# MKV31F25612 register map
Vendor: Freescale Semiconductor, Inc.; Series: Kinetis_V; File version: 1.6
CPU: CM4 r0p1, little endian, no MPU, FPU, VTOR, 4 interrupt priority bits
Registers are 32-bit, read-write, reset 0x0 unless marked. A register's access mark holds for its fields unless they carry their own. Offsets are from the block's base; [hi:lo] are bit positions; {n}, {i} and the like mark numbered series.

## DAC0 — 12-Bit Digital-to-Analog Converter
Base 0x4003F000; register names take the prefix DAC0_
{0x0+2i} DAT{i}L (i=0..15) 8-bit — DAC Data Low Register
  [7:0] DATA0 — When the DAC buffer is not enabled, DATA[11:0] controls the output voltage based on the following formula: V out = V in * (1 + DACDAT0[11:0])/4096 When the DAC buffer is enabled, DATA is mapped to the 16-word buffer
{0x1+2i} DAT{i}H (i=0..15) 8-bit — DAC Data High Register
  [3:0] DATA1 — When the DAC Buffer is not enabled, DATA[11:0] controls the output voltage based on the following formula
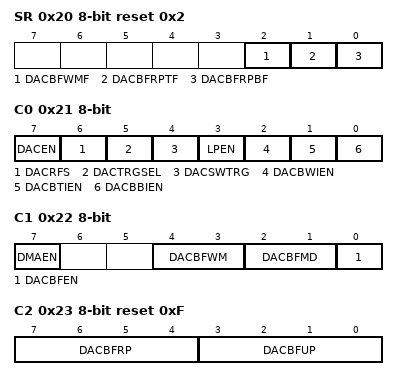
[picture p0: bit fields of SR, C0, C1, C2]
0x20 SR 8-bit reset 0x2 — DAC Status Register
  [2] DACBFWMF — DAC Buffer Watermark Flag
    0=The DAC buffer read pointer has not reached the watermark level; 1=The DAC buffer read pointer has reached the watermark level
  [1] DACBFRPTF — DAC Buffer Read Pointer Top Position Flag
    0=The DAC buffer read pointer is not zero; 1=The DAC buffer read pointer is zero
  [0] DACBFRPBF — DAC Buffer Read Pointer Bottom Position Flag
    0=The DAC buffer read pointer is not equal to C2[DACBFUP]; 1=The DAC buffer read pointer is equal to C2[DACBFUP]
0x21 C0 8-bit — DAC Control Register
  [7] DACEN — DAC Enable
    0=The DAC system is disabled; 1=The DAC system is enabled
  [6] DACRFS — DAC Reference Select
    0=The DAC selects DACREF_1 as the reference voltage; 1=The DAC selects DACREF_2 as the reference voltage
  [5] DACTRGSEL — DAC Trigger Select
    0=The DAC hardware trigger is selected; 1=The DAC software trigger is selected
  [4] DACSWTRG wo — DAC Software Trigger
    0=The DAC soft trigger is not valid; 1=The DAC soft trigger is valid
  [3] LPEN — DAC Low Power Control
    0=High-Power mode; 1=Low-Power mode
  [2] DACBWIEN — DAC Buffer Watermark Interrupt Enable
    0=The DAC buffer watermark interrupt is disabled; 1=The DAC buffer watermark interrupt is enabled
  [1] DACBTIEN — DAC Buffer Read Pointer Top Flag Interrupt Enable
    0=The DAC buffer read pointer top flag interrupt is disabled; 1=The DAC buffer read pointer top flag interrupt is enabled
  [0] DACBBIEN — DAC Buffer Read Pointer Bottom Flag Interrupt Enable
    0=The DAC buffer read pointer bottom flag interrupt is disabled; 1=The DAC buffer read pointer bottom flag interrupt is enabled
0x22 C1 8-bit — DAC Control Register 1
  [7] DMAEN — DMA Enable Select
    0=DMA is disabled; 1=DMA is enabled. When DMA is enabled, the DMA request will be generated by original interrupts. The interrupts will not be presented on this module at the same time.
  [4:3] DACBFWM — DAC Buffer Watermark Select
    0=In normal mode, 1 word . In FIFO mode, 2 or less than 2 data remaining in FIFO will set watermark status bit.; 1=In normal mode, 2 words . In FIFO mode, Max/4 or less than Max/4 data remaining in FIFO will set watermark status bit.; 2=In normal mode, 3 words . In FIFO mode, Max/2 or less than Max/2 data remaining in FIFO will set watermark status bit.; 3=In normal mode, 4 words . In FIFO mode, Max-2 or less than Max-2 data remaining in FIFO will set watermark status bit.
  [2:1] DACBFMD — DAC Buffer Work Mode Select
    0=Normal mode; 1=Swing mode; 2=One-Time Scan mode; 3=FIFO mode
  [0] DACBFEN — DAC Buffer Enable
    0=Buffer read pointer is disabled. The converted data is always the first word of the buffer.; 1=Buffer read pointer is enabled. The converted data is the word that the read pointer points to. It means converted data can be from any word of the buffer.
0x23 C2 8-bit reset 0xF — DAC Control Register 2
  [7:4] DACBFRP — DAC Buffer Read Pointer
  [3:0] DACBFUP — DAC Buffer Upper Limit

## LPTMR0 — Low Power Timer
Base 0x40040000; register names take the prefix LPTMR0_
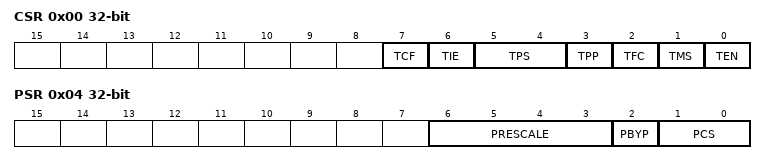
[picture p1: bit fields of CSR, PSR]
0x00 CSR — Low Power Timer Control Status Register
  [7] TCF — Timer Compare Flag
    0=The value of CNR is not equal to CMR and increments; 1=The value of CNR is equal to CMR and increments
  [6] TIE — Timer Interrupt Enable
    0=Timer interrupt disabled; 1=Timer interrupt enabled
  [5:4] TPS — Timer Pin Select
    {v}=Pulse counter input {v} is selected (v=0..3)
  [3] TPP — Timer Pin Polarity
    0=Pulse Counter input source is active-high, and the CNR will increment on the rising-edge; 1=Pulse Counter input source is active-low, and the CNR will increment on the falling-edge
  [2] TFC — Timer Free-Running Counter
    0=CNR is reset whenever TCF is set; 1=CNR is reset on overflow
  [1] TMS — Timer Mode Select
    0=Time Counter mode; 1=Pulse Counter mode
  [0] TEN — Timer Enable
    0=LPTMR is disabled and internal logic is reset; 1=LPTMR is enabled
0x04 PSR — Low Power Timer Prescale Register
  [6:3] PRESCALE — Prescale Value
    0=Prescaler divides the prescaler clock by 2; glitch filter does not support this configuration; 1=Prescaler divides the prescaler clock by 4; glitch filter recognizes change on input pin after 2 rising clock edges; 2=Prescaler divides the prescaler clock by 8; glitch filter recognizes change on input pin after 4 rising clock edges; 3=Prescaler divides the prescaler clock by 16; glitch filter recognizes change on input pin after 8 rising clock edges; 4=Prescaler divides the prescaler clock by 32; glitch filter recognizes change on input pin after 16 rising clock edges; 5=Prescaler divides the prescaler clock by 64; glitch filter recognizes change on input pin after 32 rising clock edges; 6=Prescaler divides the prescaler clock by 128; glitch filter recognizes change on input pin after 64 rising clock edges; 7=Prescaler divides the prescaler clock by 256; glitch filter recognizes change on input pin after 128 rising clock edges; 8=Prescaler divides the prescaler clock by 512; glitch filter recognizes change on input pin after 256 rising clock edges; 9=Prescaler divides the prescaler clock by 1024; glitch filter recognizes change on input pin after 512 rising clock edges; 10=Prescaler divides the prescaler clock by 2048; glitch filter recognizes change on input pin after 1024 rising clock edges; 11=Prescaler divides the prescaler clock by 4096; glitch filter recognizes change on input pin after 2048 rising clock edges; 12=Prescaler divides the prescaler clock by 8192; glitch filter recognizes change on input pin after 4096 rising clock edges; 13=Prescaler divides the prescaler clock by 16,384; glitch filter recognizes change on input pin after 8192 rising clock edges; 14=Prescaler divides the prescaler clock by 32,768; glitch filter recognizes change on input pin after 16,384 rising clock edges; 15=Prescaler divides the prescaler clock by 65,536; glitch filter recognizes change on input pin after 32,768 rising clock edges
  [2] PBYP — Prescaler Bypass
    0=Prescaler/glitch filter is enabled; 1=Prescaler/glitch filter is bypassed
  [1:0] PCS — Prescaler Clock Select
    {v}=Prescaler/glitch filter clock {v} selected (v=0..3)
0x08 CMR — Low Power Timer Compare Register
  [15:0] COMPARE — Compare Value
0x0C CNR — Low Power Timer Counter Register
  [15:0] COUNTER — Counter Value

## Notices in the file
Redistribution and use in source and binary forms, with or without modification,
are permitted provided that the following conditions are met:
o Redistributions of source code must retain the above copyright notice, this list
of conditions and the following disclaimer.
o Redistributions in binary form must reproduce the above copyright notice, this
list of conditions and the following disclaimer in the documentation and/or
other materials provided with the distribution.
o Neither the name of Freescale Semiconductor, Inc. nor the names of its
contributors may be used to endorse or promote products derived from this
software without specific prior written permission.
THIS SOFTWARE IS PROVIDED BY THE COPYRIGHT HOLDERS AND CONTRIBUTORS "AS IS" AND
ANY EXPRESS OR IMPLIED WARRANTIES, INCLUDING, BUT NOT LIMITED TO, THE IMPLIED
WARRANTIES OF MERCHANTABILITY AND FITNESS FOR A PARTICULAR PURPOSE ARE
DISCLAIMED. IN NO EVENT SHALL THE COPYRIGHT HOLDER OR CONTRIBUTORS BE LIABLE FOR
ANY DIRECT, INDIRECT, INCIDENTAL, SPECIAL, EXEMPLARY, OR CONSEQUENTIAL DAMAGES
(INCLUDING, BUT NOT LIMITED TO, PROCUREMENT OF SUBSTITUTE GOODS OR SERVICES;
LOSS OF USE, DATA, OR PROFITS; OR BUSINESS INTERRUPTION) HOWEVER CAUSED AND ON
ANY THEORY OF LIABILITY, WHETHER IN CONTRACT, STRICT LIABILITY, OR TORT
(INCLUDING NEGLIGENCE OR OTHERWISE) ARISING IN ANY WAY OUT OF THE USE OF THIS
SOFTWARE, EVEN IF ADVISED OF THE POSSIBILITY OF SUCH DAMAGE.
